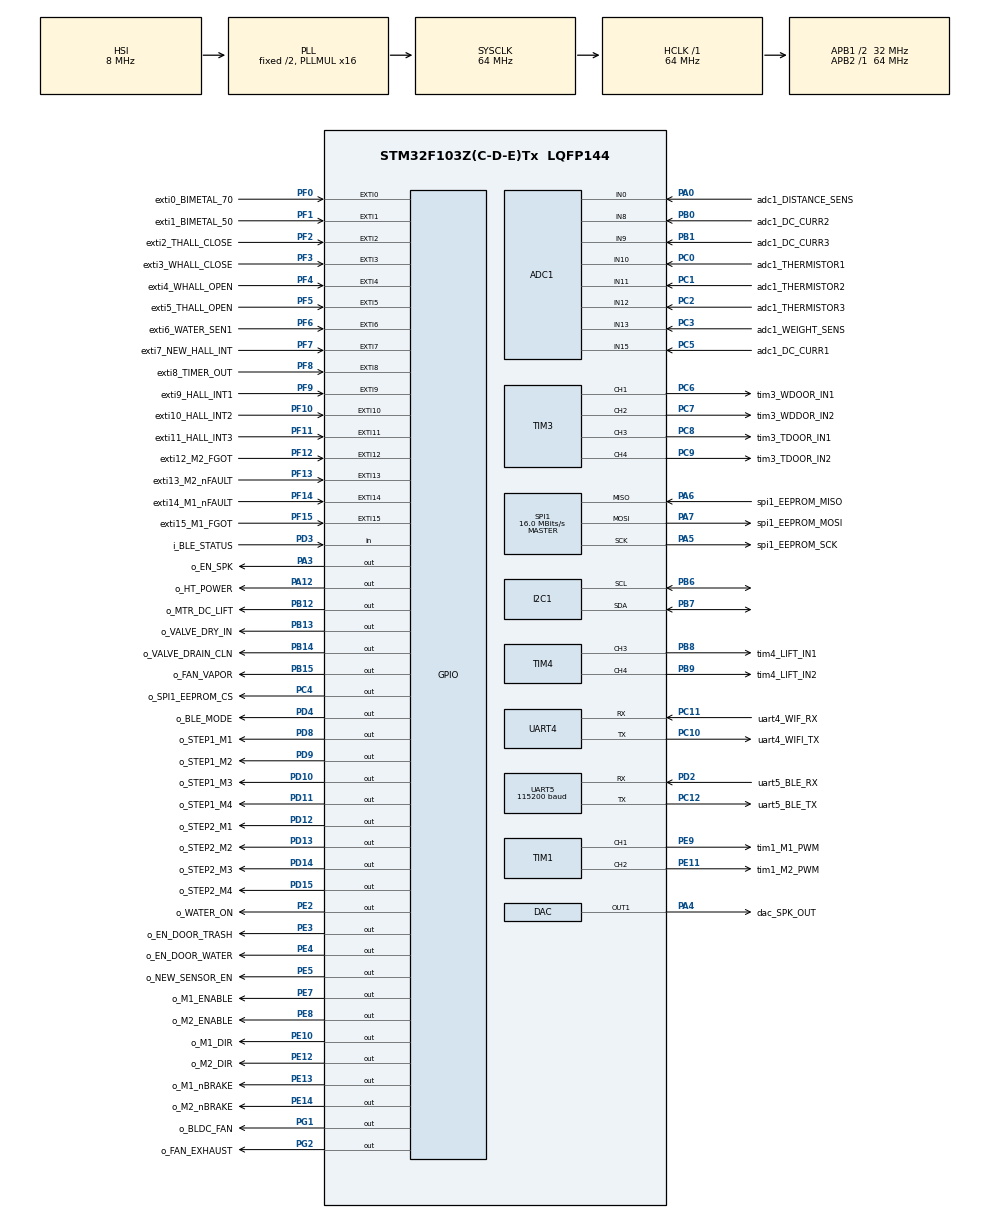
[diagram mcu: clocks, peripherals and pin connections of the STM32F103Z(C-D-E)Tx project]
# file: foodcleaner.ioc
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ADC1.Channel-1\#ChannelRegularConversion=ADC_CHANNEL_0
ADC1.Channel-2\#ChannelRegularConversion=ADC_CHANNEL_10
ADC1.Channel-3\#ChannelRegularConversion=ADC_CHANNEL_11
ADC1.Channel-4\#ChannelRegularConversion=ADC_CHANNEL_12
ADC1.Channel-5\#ChannelRegularConversion=ADC_CHANNEL_15
ADC1.Channel-6\#ChannelRegularConversion=ADC_CHANNEL_8
ADC1.Channel-7\#ChannelRegularConversion=ADC_CHANNEL_9
ADC1.Channel-8\#ChannelRegularConversion=ADC_CHANNEL_13
ADC1.NbrOfConversion=8
ADC1.NbrOfConversionFlag=1
ADC1.Rank-1\#ChannelRegularConversion=1
ADC1.Rank-2\#ChannelRegularConversion=2
ADC1.Rank-3\#ChannelRegularConversion=3
ADC1.Rank-4\#ChannelRegularConversion=4
ADC1.Rank-5\#ChannelRegularConversion=5
ADC1.Rank-6\#ChannelRegularConversion=6
ADC1.Rank-7\#ChannelRegularConversion=7
ADC1.Rank-8\#ChannelRegularConversion=8
ADC1.SamplingTime-1\#ChannelRegularConversion=ADC_SAMPLETIME_71CYCLES_5
ADC1.SamplingTime-2\#ChannelRegularConversion=ADC_SAMPLETIME_71CYCLES_5
ADC1.SamplingTime-3\#ChannelRegularConversion=ADC_SAMPLETIME_71CYCLES_5
ADC1.SamplingTime-4\#ChannelRegularConversion=ADC_SAMPLETIME_71CYCLES_5
ADC1.SamplingTime-5\#ChannelRegularConversion=ADC_SAMPLETIME_71CYCLES_5
ADC1.SamplingTime-6\#ChannelRegularConversion=ADC_SAMPLETIME_71CYCLES_5
ADC1.SamplingTime-7\#ChannelRegularConversion=ADC_SAMPLETIME_71CYCLES_5
ADC1.SamplingTime-8\#ChannelRegularConversion=ADC_SAMPLETIME_71CYCLES_5
ADC1.master=1
FREERTOS.Mutexes01=i2c1_mutex,Dynamic,NULL,Available
FREERTOS.Tasks01=defaultTask,24,256,StartDefaultTask,Default,NULL,Dynamic,NULL,NULL
FREERTOS.configTOTAL_HEAP_SIZE=8192
FREERTOS.configUSE_NEWLIB_REENTRANT=1
Mcu.Family=STM32F1
Mcu.Name=STM32F103Z(C-D-E)Tx
Mcu.Package=LQFP144
NVIC.EXTI0_IRQn=true\:5\:0\:false\:false\:true\:true\:true\:true\:true
NVIC.EXTI15_10_IRQn=true\:5\:0\:false\:false\:true\:true\:true\:true\:true
NVIC.EXTI1_IRQn=true\:5\:0\:false\:false\:true\:true\:true\:true\:true
NVIC.EXTI2_IRQn=true\:5\:0\:false\:false\:true\:true\:true\:true\:true
NVIC.EXTI3_IRQn=true\:5\:0\:false\:false\:true\:true\:true\:true\:true
NVIC.EXTI4_IRQn=true\:5\:0\:false\:false\:true\:true\:true\:true\:true
NVIC.EXTI9_5_IRQn=true\:5\:0\:false\:false\:true\:true\:true\:true\:true
NVIC.PriorityGroup=NVIC_PRIORITYGROUP_4
NVIC.TIM6_IRQn=true\:15\:0\:false\:false\:true\:false\:false\:true\:true
NVIC.TIM7_IRQn=true\:5\:0\:false\:false\:true\:true\:true\:true\:true
NVIC.TimeBase=TIM6_IRQn
NVIC.TimeBaseIP=TIM6
NVIC.UART4_IRQn=true\:5\:0\:false\:false\:true\:true\:true\:true\:true
NVIC.UART5_IRQn=true\:5\:0\:false\:false\:true\:true\:true\:true\:true
PA0-WKUP.GPIO_Label=adc1_DISTANCE_SENS
PA0-WKUP.Signal=ADCx_IN0
PA12.GPIO_Label=o_HT_POWER
PA12.Signal=GPIO_Output
PA13.Mode=Serial_Wire
PA13.Signal=SYS_JTMS-SWDIO
PA14.Mode=Serial_Wire
PA14.Signal=SYS_JTCK-SWCLK
PA3.GPIO_Label=o_EN_SPK
PA3.Signal=GPIO_Output
PA4.GPIO_Label=dac_SPK_OUT
PA4.Signal=COMP_DAC1_group
PA5.GPIO_Label=spi1_EEPROM_SCK
PA5.Mode=Full_Duplex_Master
PA5.Signal=SPI1_SCK
PA6.GPIO_Label=spi1_EEPROM_MISO
PA6.Mode=Full_Duplex_Master
PA6.Signal=SPI1_MISO
PA7.GPIO_Label=spi1_EEPROM_MOSI
PA7.Mode=Full_Duplex_Master
PA7.Signal=SPI1_MOSI
PB0.GPIO_Label=adc1_DC_CURR2
PB0.Signal=ADCx_IN8
PB1.GPIO_Label=adc1_DC_CURR3
PB1.Signal=ADCx_IN9
PB12.GPIO_Label=o_MTR_DC_LIFT
PB12.Signal=GPIO_Output
PB13.GPIO_Label=o_VALVE_DRY_IN
PB13.Signal=GPIO_Output
PB14.GPIO_Label=o_VALVE_DRAIN_CLN
PB14.Signal=GPIO_Output
PB15.GPIO_Label=o_FAN_VAPOR
PB15.Signal=GPIO_Output
PB6.Mode=I2C
PB6.Signal=I2C1_SCL
PB7.Mode=I2C
PB7.Signal=I2C1_SDA
PB8.GPIO_Label=tim4_LIFT_IN1
PB8.Signal=S_TIM4_CH3
PB9.GPIO_Label=tim4_LIFT_IN2
PB9.Signal=S_TIM4_CH4
PC0.GPIO_Label=adc1_THERMISTOR1
PC0.Signal=ADCx_IN10
PC1.GPIO_Label=adc1_THERMISTOR2
PC1.Signal=ADCx_IN11
PC10.GPIO_Label=uart4_WIFI_TX
PC10.Mode=Asynchronous
PC10.Signal=UART4_TX
PC11.GPIO_Label=uart4_WIF_RX
PC11.Mode=Asynchronous
PC11.Signal=UART4_RX
PC12.GPIO_Label=uart5_BLE_TX
PC12.Mode=Asynchronous
PC12.Signal=UART5_TX
PC2.GPIO_Label=adc1_THERMISTOR3
PC2.Signal=ADCx_IN12
PC3.GPIO_Label=adc1_WEIGHT_SENS
PC3.Signal=ADCx_IN13
PC4.GPIO_Label=o_SPI1_EEPROM_CS
PC4.PinState=GPIO_PIN_SET
PC4.Signal=GPIO_Output
PC5.GPIO_Label=adc1_DC_CURR1
PC5.Signal=ADCx_IN15
PC6.GPIO_Label=tim3_WDOOR_IN1
PC6.Signal=S_TIM3_CH1
PC7.GPIO_Label=tim3_WDDOR_IN2
PC7.Signal=S_TIM3_CH2
PC8.GPIO_Label=tim3_TDOOR_IN1
PC8.Signal=S_TIM3_CH3
PC9.GPIO_Label=tim3_TDOOR_IN2
PC9.Signal=S_TIM3_CH4
PD10.GPIO_Label=o_STEP1_M3
PD10.Signal=GPIO_Output
PD11.GPIO_Label=o_STEP1_M4
PD11.Signal=GPIO_Output
PD12.GPIO_Label=o_STEP2_M1
PD12.Signal=GPIO_Output
PD13.GPIO_Label=o_STEP2_M2
PD13.Signal=GPIO_Output
PD14.GPIO_Label=o_STEP2_M3
PD14.Signal=GPIO_Output
PD15.GPIO_Label=o_STEP2_M4
PD15.Signal=GPIO_Output
PD2.GPIO_Label=uart5_BLE_RX
PD2.Mode=Asynchronous
PD2.Signal=UART5_RX
PD3.GPIO_Label=i_BLE_STATUS
PD3.Signal=GPIO_Input
PD4.GPIO_Label=o_BLE_MODE
PD4.Signal=GPIO_Output
PD8.GPIO_Label=o_STEP1_M1
PD8.Signal=GPIO_Output
PD9.GPIO_Label=o_STEP1_M2
PD9.Signal=GPIO_Output
PE10.GPIO_Label=o_M1_DIR
PE10.Signal=GPIO_Output
PE11.GPIO_Label=tim1_M2_PWM
PE11.Signal=S_TIM1_CH2
PE12.GPIO_Label=o_M2_DIR
PE12.Signal=GPIO_Output
PE13.GPIO_Label=o_M1_nBRAKE
PE13.PinState=GPIO_PIN_SET
PE13.Signal=GPIO_Output
PE14.GPIO_Label=o_M2_nBRAKE
PE14.PinState=GPIO_PIN_SET
PE14.Signal=GPIO_Output
PE2.GPIO_Label=o_WATER_ON
PE2.Signal=GPIO_Output
PE3.GPIO_Label=o_EN_DOOR_TRASH
PE3.Signal=GPIO_Output
PE4.GPIO_Label=o_EN_DOOR_WATER
PE4.Signal=GPIO_Output
PE5.GPIO_Label=o_NEW_SENSOR_EN
PE5.Signal=GPIO_Output
PE7.GPIO_Label=o_M1_ENABLE
PE7.Signal=GPIO_Output
PE8.GPIO_Label=o_M2_ENABLE
PE8.Signal=GPIO_Output
PE9.GPIO_Label=tim1_M1_PWM
PE9.Signal=S_TIM1_CH1
PF0.GPIO_Label=exti0_BIMETAL_70
PF0.GPIO_ModeDefaultEXTI=GPIO_MODE_IT_FALLING
PF0.Signal=GPXTI0
PF1.GPIO_Label=exti1_BIMETAL_50
PF1.GPIO_ModeDefaultEXTI=GPIO_MODE_IT_FALLING
PF1.Signal=GPXTI1
PF10.GPIO_Label=exti10_HALL_INT2
PF10.GPIO_ModeDefaultEXTI=GPIO_MODE_IT_FALLING
PF10.Signal=GPXTI10
PF11.GPIO_Label=exti11_HALL_INT3
PF11.GPIO_ModeDefaultEXTI=GPIO_MODE_IT_FALLING
PF11.Signal=GPXTI11
PF12.GPIO_Label=exti12_M2_FGOT
PF12.GPIO_ModeDefaultEXTI=GPIO_MODE_IT_FALLING
PF12.Signal=GPXTI12
PF13.GPIO_Label=exti13_M2_nFAULT
PF13.GPIO_ModeDefaultEXTI=GPIO_MODE_IT_FALLING
PF13.Signal=GPXTI13
PF14.GPIO_Label=exti14_M1_nFAULT
PF14.GPIO_ModeDefaultEXTI=GPIO_MODE_IT_FALLING
PF14.Signal=GPXTI14
PF15.GPIO_Label=exti15_M1_FGOT
PF15.GPIO_ModeDefaultEXTI=GPIO_MODE_IT_FALLING
PF15.Signal=GPXTI15
PF2.GPIO_Label=exti2_THALL_CLOSE
PF2.GPIO_ModeDefaultEXTI=GPIO_MODE_IT_FALLING
PF2.Signal=GPXTI2
PF3.GPIO_Label=exti3_WHALL_CLOSE
PF3.GPIO_ModeDefaultEXTI=GPIO_MODE_IT_FALLING
PF3.Signal=GPXTI3
PF4.GPIO_Label=exti4_WHALL_OPEN
PF4.GPIO_ModeDefaultEXTI=GPIO_MODE_IT_FALLING
PF4.Signal=GPXTI4
PF5.GPIO_Label=exti5_THALL_OPEN
PF5.GPIO_ModeDefaultEXTI=GPIO_MODE_IT_FALLING
PF5.Signal=GPXTI5
PF6.GPIO_Label=exti6_WATER_SEN1
PF6.GPIO_ModeDefaultEXTI=GPIO_MODE_IT_FALLING
PF6.Signal=GPXTI6
PF7.GPIO_Label=exti7_NEW_HALL_INT
PF7.GPIO_ModeDefaultEXTI=GPIO_MODE_IT_FALLING
PF7.Signal=GPXTI7
PF8.GPIO_Label=exti8_TIMER_OUT
PF8.GPIO_ModeDefaultEXTI=GPIO_MODE_IT_FALLING
PF8.Signal=GPXTI8
PF9.GPIO_Label=exti9_HALL_INT1
PF9.GPIO_ModeDefaultEXTI=GPIO_MODE_IT_FALLING
PF9.Signal=GPXTI9
PG1.GPIO_Label=o_BLDC_FAN
PG1.Signal=GPIO_Output
PG2.GPIO_Label=o_FAN_EXHAUST
PG2.Signal=GPIO_Output
ProjectManager.HeapSize=0x200
ProjectManager.StackSize=0x400
ProjectManager.TargetToolchain=STM32CubeIDE
RCC.ADCPresc=RCC_ADCPCLK2_DIV8
RCC.AHBFreq_Value=64000000
RCC.APB1CLKDivider=RCC_HCLK_DIV2
RCC.APB1Freq_Value=32000000
RCC.APB1TimFreq_Value=64000000
RCC.APB2Freq_Value=64000000
RCC.APB2TimFreq_Value=64000000
RCC.HCLKFreq_Value=64000000
RCC.PLLMUL=RCC_PLL_MUL16
RCC.SYSCLKFreq_VALUE=64000000
RCC.SYSCLKSource=RCC_SYSCLKSOURCE_PLLCLK
RCC.USBFreq_Value=64000000
SH.ADCx_IN0.0=ADC1_IN0,IN0
SH.ADCx_IN10.0=ADC1_IN10,IN10
SH.ADCx_IN11.0=ADC1_IN11,IN11
SH.ADCx_IN12.0=ADC1_IN12,IN12
SH.ADCx_IN13.0=ADC1_IN13,IN13
SH.ADCx_IN15.0=ADC1_IN15,IN15
SH.ADCx_IN8.0=ADC1_IN8,IN8
SH.ADCx_IN9.0=ADC1_IN9,IN9
SH.COMP_DAC1_group.0=DAC_OUT1,DAC_OUT1
SH.S_TIM1_CH1.0=TIM1_CH1,PWM Generation1 CH1
SH.S_TIM1_CH2.0=TIM1_CH2,PWM Generation2 CH2
SH.S_TIM3_CH1.0=TIM3_CH1,PWM Generation1 CH1
SH.S_TIM3_CH2.0=TIM3_CH2,PWM Generation2 CH2
SH.S_TIM3_CH3.0=TIM3_CH3,PWM Generation3 CH3
SH.S_TIM3_CH4.0=TIM3_CH4,PWM Generation4 CH4
SH.S_TIM4_CH3.0=TIM4_CH3,PWM Generation3 CH3
SH.S_TIM4_CH4.0=TIM4_CH4,PWM Generation4 CH4
SPI1.BaudRatePrescaler=SPI_BAUDRATEPRESCALER_4
SPI1.CalculateBaudRate=16.0 MBits/s
SPI1.Direction=SPI_DIRECTION_2LINES
SPI1.Mode=SPI_MODE_MASTER
SPI1.VirtualType=VM_MASTER
TIM1.Channel-PWM\ Generation1\ CH1=TIM_CHANNEL_1
TIM1.Channel-PWM\ Generation2\ CH2=TIM_CHANNEL_2
TIM3.Channel-PWM\ Generation1\ CH1=TIM_CHANNEL_1
TIM3.Channel-PWM\ Generation2\ CH2=TIM_CHANNEL_2
TIM3.Channel-PWM\ Generation3\ CH3=TIM_CHANNEL_3
TIM3.Channel-PWM\ Generation4\ CH4=TIM_CHANNEL_4
TIM4.Channel-PWM\ Generation3\ CH3=TIM_CHANNEL_3
TIM4.Channel-PWM\ Generation4\ CH4=TIM_CHANNEL_4
TIM7.Period=1000
TIM7.Prescaler=64-1
UART4.VirtualMode=Asynchronous
UART5.BaudRate=115200
UART5.VirtualMode=Asynchronous
VP_FREERTOS_VS_CMSIS_V2.Mode=CMSIS_V2
VP_SYS_VS_tim6.Mode=TIM6
VP_TIM7_VS_ClockSourceINT.Mode=Enable_Timer
board=custom

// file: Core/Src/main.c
/* USER CODE BEGIN Header */
/**
  ******************************************************************************
  * @file           : main.c
  * @brief          : Main program body
  ******************************************************************************
  * @attention
  *
  * Copyright (c) 2026 STMicroelectronics.
  * All rights reserved.
  *
  * This software is licensed under terms that can be found in the LICENSE file
  * in the root directory of this software component.
  * If no LICENSE file comes with this software, it is provided AS-IS.
  *
  ******************************************************************************
  */
/* USER CODE END Header */
#include "main.h"
#include "cmsis_os.h"
#include "adc.h"
#include "dac.h"
#include "i2c.h"
#include "spi.h"
#include "tim.h"
#include "usart.h"
#include "gpio.h"

/* USER CODE BEGIN Includes */
#include "gpio_ctrl.h"
#include "drv8306.h"
#include "lift_motor.h"
#include "wifi.h"
#include "ble.h"
#include "uart_ctrl.h"
#include "protocol_r0.h"
#include "lm4871.h"
#include "w25q128.h"
#include "voice.h"
#include "tb_doorhall.h"
/* USER CODE END Includes */

/* USER CODE BEGIN PV */

/* U21 W25Q128 boot probe result, kept for the debugger/bench (§0.11).
 * g_w25q_jedec_id is the RAW answer to 9Fh, stored whether or not it matched,
 * so a failed probe still shows what came off the bus:
 *   0xEF4018 + W25Q_OK  -> chip alive
 *   0xFFFFFF            -> MISO never driven (SB21/SB22 open, R81 open, no part)
 *   0x000000            -> MISO stuck LOW
 * Nothing consumes the flash yet; a failure here is not fatal. */
volatile w25q_status_t g_w25q_init_status = W25Q_ERROR;
volatile uint32_t      g_w25q_jedec_id    = 0u;

/* USER CODE END PV */

void SystemClock_Config(void);
void MX_FREERTOS_Init(void);

int main(void)
{

  /* MCU Configuration--------------------------------------------------------*/

  /* Reset of all peripherals, Initializes the Flash interface and the Systick. */
  HAL_Init();

  /* Configure the system clock */
  SystemClock_Config();

  /* Initialize all configured peripherals */
  MX_GPIO_Init();
  MX_ADC1_Init();
  MX_DAC_Init();
  MX_I2C1_Init();
  MX_SPI1_Init();
  MX_TIM1_Init();
  MX_UART4_Init();
  MX_UART5_Init();
  MX_TIM7_Init();
  MX_TIM3_Init();
  MX_TIM4_Init();
  /* USER CODE BEGIN 2 */

  /* Door-EN outputs are on PE3 (o_EN_DOOR_TRASH) / PE4 (o_EN_DOOR_WATER) --
   * ordinary GPIO, no AFIO remap needed. (R1 net-list routes these two signals
   * to the OSC_IN/OSC_OUT pins, which are dedicated oscillator pins on the
   * STM32F103ZET6 LQFP144 and cannot be GPIO; the board reroutes them to
   * PE3/PE4.) */

  /* U6 Lift DRV8871 -- IN1/IN2 now on PB8/PB9 = TIM4_CH3/CH4 (R1), so the lift
   * is a TIM4 PWM driver like the TIM3 doors (U5/U7). Bring it to a safe state
   * (VM off, coast) before the scheduler starts. */
  Lift_Init();

  /* Comms modules: arm the UART RX interrupts before the scheduler starts.
   * Must run after MX_UART4_Init()/MX_UART5_Init() above.
   *   UART4 -> WiFi_Init (ESP-AT)
   *   UART5 -> UartCtrl_Init (protocol_r0 transport)
   *
   * ★UART5: the ble.c driver is disabled as a whole (BLE_ENABLE=0 in ble.h).
   * HAL allows only one armed RX per port, so the module that owns the data path
   * must be the one that arms it, and here that owner is uart_ctrl (the R0 packet
   * transport). The BoT-nLE521 needs no driver for this: in BYPASS mode it passes
   * the HOST UART straight through to the app, and selecting BYPASS is just
   * o_BLE_MODE LOW, done directly below. See ble.h for how to bring the driver
   * back if AT-mode configuration is ever needed. */
  WiFi_Init();
  gpio_ctrl_off(GPIO_OUT_BLE_MODE);   /* BoT-nLE521 BYPASS (was BLE_SetMode) */
  UartCtrl_Init();
  /* App-facing R0 protocol state (monitoring mask/period, RX decoder). Safe to
   * init before the scheduler: it only touches its own context. */
  Proto_Init();

  /* Front-panel keypad + LED latch on I2C1 (U8=DIS-LED @0x39, U9=DIS-SW @0x38):
   * the generic press-to-toggle membrane driver (ExtGpio/membrane.*) was REMOVED
   * on 2026-08-18 - the product does not control anything from these buttons.
   * U8/U9 now have a single owner, the tb_tca9554 testbed, which configures both
   * expanders itself in TB_TCA9554_Init() (StartMotorTask, freertos.c) and maps
   * key presses to the BLDC test motors while in APP_MODE_TESTBENCH. */

  /* U21 W25Q128 -- 16MB SPI NOR (the "EEPROM" on the schematic) on SPI1 with
   * /CS = PC4. Probe only: read the JEDEC id and record the outcome. Must run
   * after MX_SPI1_Init()/MX_GPIO_Init() above, and it is safe here because the
   * probe is two short transactions with no BUSY wait (the scheduler is not up
   * yet, so the driver's osDelay() yield must not be reached -- see w25q128.c).
   *
   * The voice player (4단계) is what will actually use the flash; until then
   * this only tells the bench whether the part answers. A failure is NOT fatal
   * -- the machine runs without voice -- so nothing is gated on it. If the id
   * comes back 0xFFFFFF, check SB21/SB22 (the /WP and /HOLD pull-up bridges)
   * and R81/R82 before suspecting the part. (§0.11, HW미검증 1-17) */
  {
    uint32_t w25q_id = 0u;
    (void)W25Q_ReadID(&w25q_id);        /* raw id first: kept even on BAD_ID */
    g_w25q_jedec_id    = w25q_id;
    g_w25q_init_status = W25Q_Init();
  }

  /* U15 LM4871 speaker amplifier driven by the DAC: PA4 (DAC_OUT1) -> Ci/Ri ->
   * -IN, shutdown on PA3 (o_EN_SPK, active-low). Must run after MX_DAC_Init()
   * and MX_GPIO_Init() above. Init parks the DAC at mid-scale and leaves the
   * amp muted; the short power-on beep confirms the audio path end-to-end.
   * (Blocking ~120ms via the DWT delay -- fine here, before the scheduler.) */
  LM4871_BoardInit();
  LM4871_Beep(&lm4871, 2000u, 120u);

  /* 음성 재생기: TIM2(16kHz TRGO) + DAC DMA2_CH3 를 코드로 설정한다.
   * .ioc 에 없는 설정이라 CubeMX 재생성이 지우지 않는다 - 4단계에서
   * ioc-6~8 로 정식 반영할 때 이 수동 설정을 걷어낼 것(voice.h 참조).
   * MX_DAC_Init()/MX_SPI1_Init()/LM4871_BoardInit() 뒤여야 한다. */
  Voice_Init();

  /* USER CODE END 2 */

  /* Init scheduler */
  osKernelInitialize();  /* Call init function for freertos objects (in cmsis_os2.c) */
  MX_FREERTOS_Init();

  /* Start scheduler */
  osKernelStart();

  /* We should never get here as control is now taken by the scheduler */

  /* Infinite loop */
  while (1)
  {

  }
}

void SystemClock_Config(void)
{
  RCC_OscInitTypeDef RCC_OscInitStruct = {0};
  RCC_ClkInitTypeDef RCC_ClkInitStruct = {0};
  RCC_PeriphCLKInitTypeDef PeriphClkInit = {0};

  /** Initializes the RCC Oscillators according to the specified parameters
  * in the RCC_OscInitTypeDef structure.
  */
  RCC_OscInitStruct.OscillatorType = RCC_OSCILLATORTYPE_HSI;
  RCC_OscInitStruct.HSIState = RCC_HSI_ON;
  RCC_OscInitStruct.HSICalibrationValue = RCC_HSICALIBRATION_DEFAULT;
  RCC_OscInitStruct.PLL.PLLState = RCC_PLL_ON;
  RCC_OscInitStruct.PLL.PLLSource = RCC_PLLSOURCE_HSI_DIV2;
  RCC_OscInitStruct.PLL.PLLMUL = RCC_PLL_MUL16;
  if (HAL_RCC_OscConfig(&RCC_OscInitStruct) != HAL_OK)
  {
    Error_Handler();
  }

  /** Initializes the CPU, AHB and APB buses clocks
  */
  RCC_ClkInitStruct.ClockType = RCC_CLOCKTYPE_HCLK|RCC_CLOCKTYPE_SYSCLK
                              |RCC_CLOCKTYPE_PCLK1|RCC_CLOCKTYPE_PCLK2;
  RCC_ClkInitStruct.SYSCLKSource = RCC_SYSCLKSOURCE_PLLCLK;
  RCC_ClkInitStruct.AHBCLKDivider = RCC_SYSCLK_DIV1;
  RCC_ClkInitStruct.APB1CLKDivider = RCC_HCLK_DIV2;
  RCC_ClkInitStruct.APB2CLKDivider = RCC_HCLK_DIV1;

  if (HAL_RCC_ClockConfig(&RCC_ClkInitStruct, FLASH_LATENCY_2) != HAL_OK)
  {
    Error_Handler();
  }
  PeriphClkInit.PeriphClockSelection = RCC_PERIPHCLK_ADC;
  PeriphClkInit.AdcClockSelection = RCC_ADCPCLK2_DIV8;
  if (HAL_RCCEx_PeriphCLKConfig(&PeriphClkInit) != HAL_OK)
  {
    Error_Handler();
  }
}

/* USER CODE BEGIN 4 */

/**
  * @brief  GPIO EXTI line detection callback (single override for the build).
  * @note   Called from HAL_GPIO_EXTI_IRQHandler() (see stm32f1xx_it.c) for every
  *         configured EXTI line on a falling edge. There can be only one strong
  *         HAL_GPIO_EXTI_Callback in the image, so this is the central router:
  *           1) latch the per-pin gpio_ctrl flag for ALL EXTI pins (not consumed
  *              yet - reserved for future edge handling);
  *           2) hand the edge to the door-limit Hall testbed, which counts and
  *              timestamps the four WHALL/THALL lines here in ISR context (it
  *              self-filters by pin and is a no-op while disabled);
  *           3) forward the M1/M2 FGOUT and nFAULT lines to their DRV8306
  *              instance so tacho counting / fault latching keep working.
  * @param  GPIO_Pin : the pin (GPIO_PIN_x) that triggered the interrupt
  * @retval None
  */
void HAL_GPIO_EXTI_Callback(uint16_t GPIO_Pin)
{
  gpio_ctrl_exti_dispatch(GPIO_Pin);

  TB_DoorHall_OnEXTI(GPIO_Pin);   /* PF2..PF5 door-limit Halls, falling edge */

  switch (GPIO_Pin)
  {
  case exti15_M1_FGOT_Pin:      /* PF15 */
  case exti14_M1_nFAULT_Pin:    /* PF14 */
    DRV8306_OnEXTI(&drv8306_m1, GPIO_Pin);
    break;
  case exti12_M2_FGOT_Pin:      /* PF12 */
  case exti13_M2_nFAULT_Pin:    /* PF13 */
    DRV8306_OnEXTI(&drv8306_m2, GPIO_Pin);
    break;
  default:
    break;
  }
}

/* USER CODE END 4 */

void HAL_TIM_PeriodElapsedCallback(TIM_HandleTypeDef *htim)
{
  if (htim->Instance == TIM6)
  {
    HAL_IncTick();
  }
}

void Error_Handler(void)
{
  __disable_irq();
  while (1)
  {
  }
}

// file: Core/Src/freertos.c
/* USER CODE BEGIN Header */
/**
  ******************************************************************************
  * File Name          : freertos.c
  * Description        : Code for freertos applications
  ******************************************************************************
  * @attention
  *
  * Copyright (c) 2026 STMicroelectronics.
  * All rights reserved.
  *
  * This software is licensed under terms that can be found in the LICENSE file
  * in the root directory of this software component.
  * If no LICENSE file comes with this software, it is provided AS-IS.
  *
  ******************************************************************************
  */
/* USER CODE END Header */

#include "FreeRTOS.h"
#include "task.h"
#include "main.h"
#include "cmsis_os.h"

/* USER CODE BEGIN Includes */
#include "tb_drv8871.h"
#include "guide_edge.h"   /* 가이드(HS6) 엣지 카운터 - MotorTask 1ms 서비스 */
#include "tb_rinse.h"     /* 5단계 벤치: 엣지 계수 실측(I02) */
#include "tb_rotation.h"  /* 5단계 벤치: R3 개정4 회전수 엔진(rotation.c) 자가시험 + run F */
#if ENABLE_TESTBENCH_APP
#include "tb_app.h"       /* 벤치 원격검증 어댑터(R0 0x27/0x33) - main.h 스위치 */
#endif
#include "tb_stepmotor.h"
#include "drv8306.h"
#include "bldc_ctrl.h"
#include "keypad.h"
#include "tb_tca9554.h"
#include "tb_lift.h"
#include "tb_gpioout.h"
#include "distance.h"
#include "tb_distance.h"
#include "hallsensor.h"
#include "tb_hallsensor.h"
#include "adc_ctrl.h"
#include "thermistor.h"
#include "tb_thermistor.h"
#include "tb_heat.h"
#include "tb_speaker.h"
#include "tb_voice.h"
#include "voiceupdater.h"
#include "voice.h"
#include "tb_water.h"
#include "tb_doorhall.h"
#include "moeum.h"
#include "dongjak.h"
#include "kangeum.h"
#include "baesu.h"
#include "jungji.h"
#include "mode_arbiter.h"
#include "protocol_r0.h"
#include "tb_protocol.h"
/* USER CODE END Includes */

/* USER CODE BEGIN Variables */
/* GP2Y0A41SK distance sensor (수거통 용량 감지) -- latest readings, kept as
 * globals so they can be inspected in the debugger / consumed by other tasks. */
volatile uint16_t g_distance_mm   = 0;   /* measured distance [mm]  */
volatile uint8_t  g_bin_fill_pct  = 0;   /* bin fill level  [0..100]*/
/* NTC thermistors x3 (HCET-103F3950). Temperature in 0.1C units, so e.g.
 * 253 -> 25.3 C. THERMISTOR_ERR_D10 (-32768) means the read failed. */
volatile int16_t  g_therm_c_d10[THERMISTOR_COUNT] = {0};
/* Hall sensors HS1..HS8 via U24 TCA9554A (I2C1, INT on PF9). bit i = HS(i+1)
 * magnet present. Refreshed by StartDefaultTask; inspect in the debugger or via
 * HallSensor_Get(). */
volatile uint8_t  g_hall_mask     = 0;   /* HS1..8 detected mask [bit0..7] */

/* Runtime app mode: which of the mutually exclusive halves the two RTOS tasks
 * run -- the debug TESTBENCH (keypad/debugger-driven individual motors) or one
 * of the scenarios (모음 / 동작 / 강음 / 배수). They cannot run at once because
 * they share g_stir_ctrl (M2), the grinder and the doors, so each task branches
 * on this flag.
 *
 * OWNERSHIP MOVED (R1): app_mode_t and g_app_mode now live in
 * Core/Scenario/mode_arbiter.c. The arbiter decodes the lid-position Hall
 * sensors HS1..HS5 every 100 ms REGARDLESS of the current mode and is the only
 * writer of g_app_mode, so turning the lid cap actually starts/stops a scenario
 * (previously the trigger was gated behind the very mode it was supposed to
 * select, so only a debugger write could switch modes). The mode-transition
 * cleanup that used to live in StartMotorTask below now runs inside
 * ModeArbiter_MotorTick() -> Jungji_StopAll(), which also fixes the ordering
 * bug where the transition Abort() wiped a freshly latched start_req. */

/* Motor control service thread. Owns all motor testbeds -- DRV8871 doors (U5/
 * U7), steppers STEP1/STEP2, DRV8306 BLDC (U11/U16) and the U6 lift -- so motor
 * timing stays independent of the 100 ms sensor loop in defaultTask. */
/* 음성 재생 태스크. DAC DMA 의 HT/TC 인터럽트가 세마포어를 주면 다음 반쪽
 * (1024샘플/64ms)을 SPI 로 읽어 채운다. 채우는 일 자체는 2KB @16MHz ≈ 1.1ms
 * 라 64ms 예산에 비해 한가하다. 시나리오/모터와 독립이라 재생이 MotorTick 에
 * 영향을 주지 않는다(설계서 §7.3 비블로킹 요구). */
osThreadId_t Voice_TaskHandle;
const osThreadAttr_t Voice_Task_attributes = {
  .name = "Voice_Task",
  .stack_size = 512 * 4,
  .priority = (osPriority_t) osPriorityNormal,
};

osThreadId_t Motor_TaskHandle;
const osThreadAttr_t Motor_Task_attributes = {
  .name = "Motor_Task",
  .stack_size = 512 * 4,
  .priority = (osPriority_t) osPriorityNormal,
};
/* USER CODE END Variables */
/* Definitions for defaultTask */
osThreadId_t defaultTaskHandle;
const osThreadAttr_t defaultTask_attributes = {
  .name = "defaultTask",
  .stack_size = 256 * 4,
  .priority = (osPriority_t) osPriorityNormal,
};
/* Definitions for i2c1_mutex */
osMutexId_t i2c1_mutexHandle;
const osMutexAttr_t i2c1_mutex_attributes = {
  .name = "i2c1_mutex"
};

/* USER CODE BEGIN FunctionPrototypes */
void StartMotorTask(void *argument);
/* USER CODE END FunctionPrototypes */

void StartDefaultTask(void *argument);

void MX_FREERTOS_Init(void); /* (MISRA C 2004 rule 8.1) */

void MX_FREERTOS_Init(void) {
  /* Create the mutex(es) */
  /* creation of i2c1_mutex */
  i2c1_mutexHandle = osMutexNew(&i2c1_mutex_attributes);

  /* Create the thread(s) */
  /* creation of defaultTask */
  defaultTaskHandle = osThreadNew(StartDefaultTask, NULL, &defaultTask_attributes);

  /* USER CODE BEGIN RTOS_THREADS */
  Motor_TaskHandle = osThreadNew(StartMotorTask, NULL, &Motor_Task_attributes);
  Voice_TaskHandle = osThreadNew(Voice_Task, NULL, &Voice_Task_attributes);
  /* USER CODE END RTOS_THREADS */

}

void StartDefaultTask(void *argument)
{
  /* USER CODE BEGIN StartDefaultTask */
  /* Analog sensors on ADC1, all read through the shared adc_ctrl layer:
   *   - GP2Y0A41SK distance sensor (PA0)      -> bin fill level
   *   - 3x NTC thermistors (PC0/PC1/PC2)      -> temperatures [0.1 C]
   * AdcCtrl_Init() calibrates ADC1 and puts it in single-conversion mode; it
   * must run before any Distance_/Thermistor_ read. The distance sensor
   * refreshes every 16.5 ms, so 100 ms polling is plenty. */
  AdcCtrl_Init();
  Distance_Init();
  TB_Distance_Init();     /* enable-gated Distance-SEN monitor (defaultTask owns ADC1) */
  Thermistor_Init();
  TB_Thermistor_Init();   /* enable-gated thermistor monitor (defaultTask owns ADC1) */
  /* Heater (HT-POWER PA12) testbed. Reads the smoothed thermistor value cached
   * by Thermistor_Tick() and closes the 동작 190/195C hysteresis loop, so the
   * NTC probe is in the loop. Starts disabled/off; only drives the pin while in
   * TESTBENCH mode so it never fights the 동작 scenario over HT-POWER. */
  TB_Heat_Init();
  /* Hall sensors HS1..8 on the U24 TCA9554A (I2C1). MX_I2C1_Init() already ran
   * in main() before the scheduler, so the bus is up. U24's INT is wired to PF9
   * (HALL-INT1): the loop services that edge via HallSensor_ServiceInt() and
   * also polls periodically as a safety net. */
  HallSensor_Init();
  TB_HallSensor_Init();   /* enable-gated U24 Hall-sensor monitor (defaultTask owns the HS reads) */
  /* 가이드(교반 원점 HS6 = U24 P5 = J28-2) 엣지 카운터. R3 5단계의 cnt 20/40 이
   * 이 위에 얹힌다(설계서 공통헹굼_모듈_구조R3.md §4). 서비스는 StartMotorTask
   * (1ms)가 한다 - 100ms 폴링으로는 C007 의 감지~정지 ≤50ms 를 못 맞춘다.
   * 여기서는 카운터만 0 으로 세운다(HallSensor_Init 뒤라야 캐시가 유효). */
  GuideEdge_Init();
  /* U15 LM4871 speaker (SPK-EN PA3, SPK-DAC PA4). Enable-gated low-volume test
   * tone; no ADC1/I2C involvement so it is safe on this task. Idempotent init. */
  TB_Speaker_Init();      /* enable-gated speaker test tone (set tb_speaker_enable=1) */
  /* U21 음성 플래시(W25Q128) 벤치 - tb_speaker 와 대상이 다르다: 저쪽은 앰프/DAC
   * 출력단, 이쪽은 SPI1 위의 플래시 내용물. one-shot 커맨드 방식이라 평소에는
   * 아무것도 하지 않는다. 드라이버가 블로킹(섹터 이레이즈 최대 400ms)이라
   * 1ms MotorTask 가 아니라 반드시 이 100ms 태스크에 있어야 한다. */
  TB_Voice_Init();        /* one-shot: tb_voice_probe_once / _selftest_once 등 */
  /* 음성 이미지 다운로드 로더(1회성 정비 기능). 평소에는 완전히 비활성이고,
   * 앱/PC 가 R0 W|0x32 를 보냈을 때만 UART5 소유권을 가져간다. */
  VoiceUpdater_Init();
  /* Clean-water fill path: WATER-ON supply (PE2) + WATER-SEN1/SEN2 level sensors
   * (PF6/PF7 EXTI). Enable-gated; plain GPIO + EXTI-flag reads, so it is safe on
   * this task, which already polls the EXTI flags. */
  TB_Water_Init();        /* enable-gated water supply + level-sensor monitor (set tb_water_enable=1) */
  /* Door-limit Hall monitor: WHALL/THALL open/close (PF3/PF4/PF2/PF5 EXTI) that
   * gate the WDoor/TDoor transitions in the 모음/동작 scenarios. Enable-gated,
   * input-only (reuses WDoor_/TDoor_At* decode), so it is safe on this task and
   * never fights a scenario. */
  TB_DoorHall_Init();     /* enable-gated door-limit Hall monitor (set tb_doorhall_enable=1) */
  /* R0 protocol self-test. Pure in-memory encode/decode round trip -- it never
   * touches UART5 or the motors, so it is safe to run with the app connected
   * and a scenario in progress. Set tb_proto_run_once=1 in the debugger for a
   * single pass and read tb_proto_fails (0 = OK). See tb_protocol.h. */
  TB_Protocol_Init();
  /* NOTE: the front-panel keypad (U8/U9 TCA9554A on I2C1) is NOT serviced from
   * this task. The generic membrane driver was removed on 2026-08-18 (the
   * product controls nothing from those buttons); the only U8/U9 owner left is
   * the tb_tca9554 testbed on StartMotorTask, kept for bench motor driving in
   * APP_MODE_TESTBENCH. */
  for(;;)
  {
    g_distance_mm  = Distance_ReadMm();
    g_bin_fill_pct = Distance_FillFromMm(g_distance_mm);

    /* One ADC read-set + EMA update for all 3 probes (single owner of the
     * thermistor filter), then publish the SMOOTHED value. Thermistor_Tick()
     * must be called from here only, once per 100 ms cycle. */
    Thermistor_Tick();
    for (uint8_t i = 0; i < THERMISTOR_COUNT; i++)
    {
      g_therm_c_d10[i] = Thermistor_GetCelsius_d10(i);
    }

    /* Enable-gated Distance-SEN monitor (testbed): set tb_dist_enable=1 in the
     * debugger to refresh tb_dist_raw/volt/cm/mm/fill, 0 to stop. Safe here
     * because this task is the sole ADC1 owner. */
    TB_Distance_Poll();

    /* Enable-gated thermistor monitor (testbed): set tb_therm_enable=1 in the
     * debugger to refresh tb_therm_raw/tb_therm_c/tb_therm_c_d10, 0 to stop.
     * Safe here because this task is the sole ADC1 owner. */
    TB_Thermistor_Poll();

    /* Enable-gated heater testbed (HT-POWER PA12): set tb_heat_enable=1 in the
     * debugger to close the hysteresis loop (or MANUAL-force the pin) using the
     * smoothed temperature published just above. Passing testbench-active gates
     * it so it only drives HT-POWER outside the 동작 scenario, which otherwise
     * owns the pin from StartMotorTask. */
    TB_Heat_Poll(AppMode_IsBenchIdle(g_app_mode));

    /* Refresh the HS1..8 snapshot (bit i = HS(i+1) magnet present). U24 pulls
     * HALL-INT1 (PF9) low on any change; service that edge first for low
     * latency, then do the periodic read as a safety net for missed edges. */
    (void)HallSensor_ServiceInt();
    if (HallSensor_Update() == HAL_OK)
    {
      g_hall_mask = HallSensor_GetMask();
    }

    /* Enable-gated U24 Hall-sensor monitor (testbed): set tb_hall_enable=1 in
     * the debugger to split the P0..P7 mask into the four named channels
     * (trigger group P0..P4, 교반원점 P5, 수거통 P6, 리프트하단 P7) with
     * edge counts, 0 to stop. Safe here: this task is the sole U24 reader. */
    TB_HallSensor_Poll();

    /* Enable-gated speaker testbed: set tb_speaker_enable=1 in the debugger to
     * play a repeating low-volume tone (SPK-EN active, SPK-DAC bit-banged), 0 to
     * mute. A burst blocks this task for tb_speaker_on_ms; harmless at 100 ms. */
    TB_Speaker_Poll();

    /* U21 음성 플래시 벤치. 대기 중인 one-shot 커맨드가 없으면 즉시 반환한다.
     * 인자는 소거/기록 커맨드에만 걸리는 게이트다 - 읽기 커맨드는 SPI1 에 U21
     * 뿐이라 시나리오와 다툴 상대가 없어 모드와 무관하게 돈다(tb_voice.h).
     * 자가검사 1회는 이 태스크를 ~0.9초 묶으므로 벤치 모드에서만 허용된다. */
    TB_Voice_Poll(AppMode_IsBenchIdle(g_app_mode));

    /* Enable-gated water testbed: set tb_water_enable=1 in the debugger to open
     * WATER-ON and refresh tb_water_sen1/2_level/_present/_events, 0 to shut the
     * supply off. Reads the shared EXTI flags polled/cleared on this task.
     * Gated like TB_Heat_Poll: WATER-ON (PE2) is also driven by the Moeum/Dongjak
     * scenarios from StartMotorTask, so the bench only touches it when idle. */
    TB_Water_Poll(AppMode_IsBenchIdle(g_app_mode));

    /* Enable-gated door-limit Hall monitor (testbed): set tb_doorhall_enable=1 in
     * the debugger to refresh tb_wdoor_at_open/close, tb_tdoor_at_open/close and
     * the raw pin levels, 0 to stop. Input-only. Falling edges are NOT counted
     * here - TB_DoorHall_OnEXTI() does that from the EXTI ISR (main.c router),
     * so this poll only owns the level/at-limit snapshot. */
    TB_DoorHall_Poll();

    /* Mode arbiter. Runs on EVERY cycle, in every mode: it decodes the lid
     * position from the HS1..HS5 snapshot refreshed just above and decides the
     * mode (HS5 모음 / HS2 동작 / HS1 강음 / HS4 배수 / HS3 정지=APP_MODE_JUNGJI)
     * or requests a stop (HS3, or the lid leaving every position). It only latches
     * requests here; the switch itself is executed by ModeArbiter_MotorTick() on the
     * motor task. Must come AFTER HallSensor_Update() so it sees this cycle's
     * mask. */
    ModeArbiter_SenseTick();

    /* Scenario sensing half. Sensor-only (water level, temperature, bin fill,
     * debug force-start), so it belongs on this 100 ms cadence and never
     * touches a motor. The start trigger itself is no longer read here -- the
     * arbiter above owns it. */
    switch (g_app_mode)
    {
      case APP_MODE_MOEUM:   Moeum_SenseTick();   break;
      case APP_MODE_DONGJAK: Dongjak_SenseTick(); break;
      case APP_MODE_KANGEUM: Kangeum_SenseTick(); break;   /* 미구현 스텁 */
      case APP_MODE_BAESU:   Baesu_SenseTick();   break;   /* 미구현 스텁 */
      case APP_MODE_JUNGJI:                                /* 정지(HS3): 대기와 동일 */
      case APP_MODE_TESTBENCH:
      default:                                    break;
    }

    /* App-facing R0 protocol service (UART5 via the BLE module in BYPASS).
     * Drains the uart_ctrl RX ring, answers R/W frames, and pushes the M
     * (monitoring) packets for 모음/동작. Must come AFTER the sensor reads and
     * the scenario SenseTick above so a packet carries THIS cycle's snapshot.
     * Sensor-only + queued TX (never blocks on the UART), so it belongs on this
     * task; scenario-control writes must latch a request for MotorTask instead
     * of driving anything here. */
    Proto_Tick(HAL_GetTick());

    /* 음성 다운로드 모드면 여기서 세션 전체를 처리하고 돌아온다(수 분).
     * 그 동안 이 태스크의 센서 폴링은 멈추지만, 내부 대기가 osDelay(1)
     * 양보라 MotorTask(1ms)는 정상 동작한다. 비활성이면 즉시 반환하므로
     * 평상시 비용은 함수 호출 하나다(voiceupdater.h "태스크 영향"). */
    VoiceUpdater_Poll();

    /* Enable-gated R0 protocol self-test: set tb_proto_run_once=1 (single pass)
     * or tb_proto_enable=1 (repeating) in the debugger, then read tb_proto_fails
     * / tb_proto_first_fail. ~1-2 ms per pass; uses only its own buffers, so it
     * cannot disturb Proto_Tick above. */
    TB_Protocol_Poll();

    osDelay(100);
  }
  /* USER CODE END StartDefaultTask */
}

/* USER CODE BEGIN Application */

/**
  * @brief  Function implementing the Motor_Task thread. Owns every motor
  *         testbed. Set the matching enable flag in the debugger to run a
  *         motor, clear it to stop:
  *           tb_wdoor_enable / tb_tdoor_enable -> DRV8871 doors (U5 / U7);
  *                                stop themselves at the Hall limit for the
  *                                direction driven (tb_*_limit_stop=1 default,
  *                                result in tb_*_limit_hit)
  *           tb_step1_enable / tb_step2_enable -> steppers STEP1 / STEP2; both
  *                                are TIMED one-shots that self-clear the flag:
  *                                STEP1 runs 15 s, STEP2 runs 2 s for dir=1
  *                                (닫힘) and 1 s for dir=0 (열림)
  *           g_grind_ctrl (M1/U11) & g_stir_ctrl (M2/U16) -> DRV8306 BLDC, both
  *                                                CLOSED-LOOP: drive from the
  *                                                keypad (odd SW=M1, even SW=M2)
  *                                                or set g_*_ctrl.target_out_rpm;
  *                                                status in .meas_out_rpm/.state
  *           tb_lift_enable                    -> U6 lift (dir: tb_lift_reverse).
  *                                TIM4 HW PWM since R1; a profiled run is a
  *                                one-shot that self-clears the flag at its
  *                                time cap, or at HS8 (lift bottom) when
  *                                descending -- there is NO top limit sensor
  *         Poll all at 1 ms so the stepper pacing (tb_stepN_period_ms) is
  *         accurate; the DRV8306 testbed self-times its FGOUT window off
  *         HAL_GetTick().
  * @param  argument: Not used
  * @retval None
  */
/* TESTBENCH half (original behaviour): debugger/keypad-driven individual motors.
 * TB_TCA9554_Poll() reads the keypad and translates presses into BldcCtrl
 * commands BEFORE the control ticks apply them, so a press acts on the same
 * cycle. */
static void MotorTask_RunTestbench(uint32_t now_ms)
{
  TB_DRV8871_Poll();
  TB_StepMotor_Poll();
  /* Keypad -> BldcCtrl_Start(). Suppressed while the emergency short brake is
   * held: BldcCtrl_Start() releases nBRAKE and wakes the driver, so a keypress
   * landing inside the JUNGJI_BRAKE_MS window would spin the grinder back up
   * right after a 정지. */
  if (!Jungji_IsBraking())
  {
    TB_TCA9554_Poll();
  }
  else
  {
    Keypad_FlushEvents();   /* 제동 구간에 눌린 키는 버린다(재기동 금지) */
  }
  /* 5단계 벤치: 가이드 엣지 계수 실측 + 원샷 교반 구동(I02 확정용). BldcCtrl_Tick
   * 앞에 둬서 이 사이클의 Start/Stop 이 같은 사이클에 적용되게 한다. */
  TB_Rinse_Poll(AppMode_IsBenchIdle(g_app_mode));
  TB_Rotation_Poll(AppMode_IsBenchIdle(g_app_mode)); /* tb_rinse 와 교반 배타 */
  BldcCtrl_Tick(&g_grind_ctrl, now_ms);   /* M1 closed-loop PI (100 ms)        */
  BldcCtrl_Tick(&g_stir_ctrl,  now_ms);   /* M2 closed-loop PI (100 ms)        */
  TB_Lift_Poll();
  TB_GpioOut_Poll();                      /* drain valve + 3 fans (on/off)     */
}

/* SCENARIO half - "모음" rinse. Moeum_MotorTick() owns the state machine and
 * commands the WDoor motor + valve + stir BLDC; BldcCtrl_Tick(&g_stir_ctrl)
 * still has to run every cycle to execute the stir closed-loop PI that moeum
 * only issues Start/Stop/target to. The grinder (M1) is unused here and stays
 * parked. No TB_*_Poll runs, so nothing else touches the shared motors. */
static void MotorTask_RunMoeum(uint32_t now_ms)
{
  Moeum_MotorTick(now_ms);
  BldcCtrl_Tick(&g_stir_ctrl, now_ms);
}

/* SCENARIO half - "동작"(건조/분쇄/배출). Dongjak_MotorTick() owns the state
 * machine and commands heater/doors/steppers/fans + both BLDC via Start/Stop/
 * target; BldcCtrl_Tick(M1 grinder, M2 stirrer) must run every cycle to execute
 * their closed-loop PI. No TB_*_Poll runs, so nothing else touches the motors. */
static void MotorTask_RunDongjak(uint32_t now_ms)
{
  Dongjak_MotorTick(now_ms);
  BldcCtrl_Tick(&g_grind_ctrl, now_ms);
  BldcCtrl_Tick(&g_stir_ctrl,  now_ms);
}

/* SCENARIO half - "강음"(HS1) / "배수"(HS4). Both are UNIMPLEMENTED stubs: the
 * state machines only record that the mode was selected and drive nothing, so
 * no BldcCtrl_Tick is needed yet. Add it when the sequences are filled in. */
static void MotorTask_RunKangeum(uint32_t now_ms)
{
  Kangeum_MotorTick(now_ms);
}

static void MotorTask_RunBaesu(uint32_t now_ms)
{
  Baesu_MotorTick(now_ms);
}

void StartMotorTask(void *argument)
{
  TB_DRV8871_Init();               /* also WDoor_Init/TDoor_Init (doors)       */
  TB_StepMotor_Init();
  DRV8306_InitAll();               /* bring up drv8306_m1 + drv8306_m2         */
  BldcCtrl_Init(&g_grind_ctrl);    /* M1 (U11) grinder closed loop            */
  BldcCtrl_Init(&g_stir_ctrl);     /* M2 (U16) stirrer closed loop            */
  Keypad_Init();                   /* U31 버튼8 / U32 LED8 - 버스 단독 소유자  */
  TB_TCA9554_Init();               /* 키패드 -> BLDC 벤치 매핑(keypad 소비자)  */
  TB_Lift_Init();
  TB_GpioOut_Init();               /* drain valve + 3 fans, all forced off     */
  TB_Rinse_Init();                 /* 5단계 벤치: 가이드 엣지 계수 실측(I02)   */
  TB_Rotation_Init();              /* 5단계 벤치: 회전수 엔진(개정4)           */
#if ENABLE_TESTBENCH_APP
  TbApp_Init();                    /* 벤치 원격검증 어댑터(0x27/0x33)          */
#endif
  Moeum_Init();                    /* scenario armed but idle until selected   */
  Dongjak_Init();                  /* scenario armed but idle until selected   */
  Kangeum_Init();                  /* HS1 강음 - unimplemented stub            */
  Baesu_Init();                    /* HS4 배수 - unimplemented stub            */
  Jungji_Init();                   /* common stop handler (must precede arbiter)*/
  ModeArbiter_Init();              /* owns g_app_mode; starts in TESTBENCH      */

  for(;;)
  {
    uint32_t now = HAL_GetTick();

    /* 전면 버튼 8개(U31) + LED 8개(U32). 모드와 무관하게 매 사이클 돈다 -
     * 버튼은 시나리오 실행 중에도 눌리고, 이 드라이버가 U31/U32 의 유일한
     * 버스 소유자다. 눌림 이벤트는 래치되므로 아래 소비자들이 같은 사이클에
     * 가져가면 된다(현재 소비자는 벤치뿐 - 제품 기능 배정 I10·I14 미확정). */
    Keypad_Tick(now);

    /* 가이드(HS6) 엣지 계수. **모드와 무관하게 매 사이클** 돈다 - 5단계 헹굼이
     * 이 카운터를 그대로 쓰고, 준비 탐색/회차는 baseline 차이로 읽기 때문에
     * 시나리오 중에도 끊기면 안 된다. PF9(HALL-INT1) 플래그가 섰을 때만 U24 를
     * 읽으므로 평상시 I2C 부하는 없다(guide_edge.h 참조). */
    GuideEdge_Tick(now);

    /* Common stop handler. Consumes any pending stop request (HS3 정지, lid
     * lost, mode switch, scenario fault, debugger), releases the BLDC short
     * brake after JUNGJI_BRAKE_MS and holds the cooling fans while the pot is
     * still hot. Runs first so the arbiter below sees the settled brake state. */
    Jungji_Tick(now);

    /* Mode arbiter, motor half: the only place g_app_mode is written. Applies a
     * pending switch as stop -> switch -> start, waiting for the brake hold to
     * expire before issuing the start so a braked BLDC is never commanded to
     * spin. */
    ModeArbiter_MotorTick(now);

    switch (g_app_mode)
    {
      case APP_MODE_MOEUM:   MotorTask_RunMoeum(now);   break;
      case APP_MODE_DONGJAK: MotorTask_RunDongjak(now); break;
      case APP_MODE_KANGEUM: MotorTask_RunKangeum(now); break;
      case APP_MODE_BAESU:   MotorTask_RunBaesu(now);   break;
      /* 정지(HS3)는 대기와 같은 벤치 분기로 간다. HS3 이후 대기로 돌아가던
       * 종전 동작과 동일하게 두기 위함이다 - JUNGJI 는 '보이는 상태'일 뿐
       * 실행 성격을 바꾸지 않는다(mode_arbiter.h app_mode_t 주석 참조). */
      case APP_MODE_JUNGJI:
      case APP_MODE_TESTBENCH:
      default:               MotorTask_RunTestbench(now); break;
    }
    osDelay(1);
  }
}

/* USER CODE END Application */
